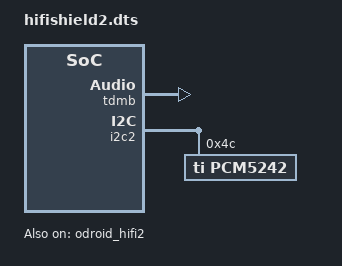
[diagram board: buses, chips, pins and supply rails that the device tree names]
/dts-v1/;
/plugin/;

/ {
	fragment@0 {
		target = <&tdmb>;
		__overlay__ {
			status = "okay";
		};
	};

	fragment@1 {
		// i2c2 aliased with i2c0.
		target = <&i2c2>;

		__overlay__ {
			status = "okay";

			#address-cells = <1>;
			#size-cells = <0>;

			pcm5242: pcm5242@4c {
				compatible = "ti,pcm5242";
				reg = <0x4c>;
				#sound-dai-cells = <0>;
				status = "okay";

				/*
				AVDD-supply = <&reg_3v3_analog>;
				DVDD-supply = <&reg_1v8>;
				CPVDD-supply = <&reg_3v3>;
				*/
			};
		};
	};

	fragment@2 {
		target = <&odroid_hifi2>;

		__overlay__ {
			compatible = "amlogic, g12a-sound-card";
			aml-audio-card,name = "ODROID-HIFI2";
			status = "okay";

			/* ODROID-C4: I2S out(J7)*/
			aml-audio-card,dai-link@0 {
				format = "i2s";
				mclk-fs = <256>;
				continuous-clock;
				bitclock-master = <&tdmb>;
				frame-master = <&tdmb>;
				cpu {
					sound-dai = <&tdmb>;
					dai-tdm-slot-tx-mask = <1 1>;
					dai-tdm-slot-rx-mask = <1 1>;
					dai-tdm-slot-num = <2>;
					dai-tdm-slot-width = <32>;
					system-clock-frequency = <12288000>;
				};
				codec {
					sound-dai = <&pcm5242 &dummy_codec>;
				};
			};
		};
	};
};
